# DEVICE_PRM register map
Vendor: Texas Instruments
Peripheral module from a debugger description file (folder DRA72x).
Registers are 32-bit, access per field, reset 0x0 unless marked. A register's access mark holds for its fields unless they carry their own. Offsets are as the file gives them; lines under a group give offsets from that group; [hi:lo] are bit positions; {n}, {i} and the like mark numbered series; 'fields as' and 'values as' point back to an identical list; <NAME> marks a mode.

## DEVICE_PRM
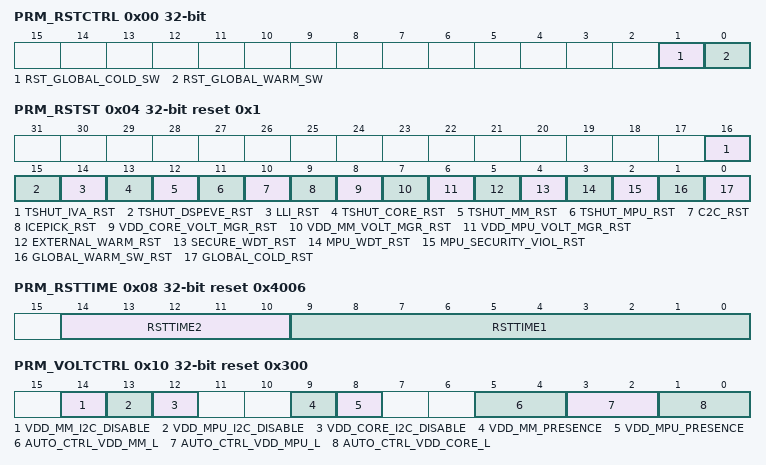
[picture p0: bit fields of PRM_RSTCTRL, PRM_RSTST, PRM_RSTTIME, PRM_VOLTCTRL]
0x00 PRM_RSTCTRL — Global software cold and warm reset control. This register is auto-cleared. Only write 1 is possible. A read returns 0 only.
  [1] RST_GLOBAL_COLD_SW rw — Global COLD software reset control. This bit is reset only upon a global cold source of reset.
    0=Global COLD software reset is cleared; 1=Triggers a global COLD software reset. The software must ensure the SDRAM is properly put in sef-refresh mode before applying this reset.
  [0] RST_GLOBAL_WARM_SW rw — Global WARM software reset control. This bit is reset upon any global source of reset (warm and cold).
    0=Global warm software reset is cleared; 1=Triggers a global warm software reset
0x04 PRM_RSTST reset 0x1 — This register logs the global reset sources. Each bit is set upon release of the domain reset signal. Must be cleared by software. [warm reset insensitive]
  [16] TSHUT_IVA_RST rw — TSHUT_IVA warm reset event. This is a source of global WARM reset.
    0=No TSHUT_MM reset; 1=TSHUT_MM reset has occurred
  [15] TSHUT_DSPEVE_RST rw — TSHUT_DSPEVE warm reset event. This is a source of global WARM reset.
    0=No TSHUT_MM reset; 1=TSHUT_MM reset has occurred
  [14] LLI_RST rw — LLI warm reset event. This is a source of global WARM reset.
    0=No LLI warm reset; 1=LLI warm reset has occurred
  [13] TSHUT_CORE_RST rw — TSHUT_CORE warm reset event. This is a source of global WARM reset.
    0=No TSHUT_CORE reset; 1=TSHUT_CORE reset has occurred
  [12] TSHUT_MM_RST rw — TSHUT_GPU warm reset event. This is a source of global WARM reset.
    0=No TSHUT_MM reset; 1=TSHUT_MM reset has occurred
  [11] TSHUT_MPU_RST rw — TSHUT_MPU warm reset event. This is a source of global WARM reset.
    0=No TSHUT_MPU reset; 1=TSHUT_MPU reset has occurred
  [10] C2C_RST rw — C2C warm reset event. This is a source of global WARM reset.
    0=No C2C warm reset; 1=C2C warm reset has occurred
  [9] ICEPICK_RST rw — IcePick reset event. This is a source of global warm reset initiated by the emulation.
    0=No ICEPICK reset; 1=IcePick reset has occurred
  [8] VDD_CORE_VOLT_MGR_RST rw — VDD_CORE voltage manager reset event This is a source of global WARM reset.
    0=No VDD_CORE voltage manager reset; 1=VDD_CORE voltage manager reset has occurred
  [7] VDD_MM_VOLT_MGR_RST rw — VDD_MM voltage manager reset event This is a source of global WARM reset.
    0=No VDD_MM voltage manager reset; 1=VDD_MM voltage manager reset has occurred
  [6] VDD_MPU_VOLT_MGR_RST rw — VDD_MPU voltage manager reset event This is a source of global WARM reset.
    0=No VDD_MPU voltage manager reset; 1=VDD_MPU voltage manager reset has occurred
  [5] EXTERNAL_WARM_RST rw — External warm reset event
    0=No global warm reset; 1=Global external warm reset has occurred
  [4] SECURE_WDT_RST rw — Secure Watchdog timer or HDCP reset event. This is a source of global WARM reset.
    0=No Secure watchdog / HDCP reset; 1=Secure wachtdog or HDCP reset has occurred
  [3] MPU_WDT_RST rw — WD_TIMER2 and MPU subsystem watchdog reset event. This is a source of global WARM reset.
    0=No reset; 1=Reset has occurred
  [2] MPU_SECURITY_VIOL_RST rw — Security violation reset event triggered by Security State Machine inside MPUSS. This is a source of global WARM reset.
    0=No security violation reset; 1=Security violation reset has occurred
  [1] GLOBAL_WARM_SW_RST rw — Global warm software reset event
    0=No global warm SW reset; 1=Global warm SW reset has occurred
  [0] GLOBAL_COLD_RST rw — Power-on (cold) reset event
    0=No power-on reset; 1=Power-on reset has occurred
0x08 PRM_RSTTIME reset 0x4006 — Reset duration control. [warm reset insensitive]
  [14:10] RSTTIME2 rw — Power domain reset duration 2 in number of RM.SYSCLK clock cycles.
  [9:0] RSTTIME1 rw — Global reset duration 1 in number of FUNC_32K_CLK clock cycles. This bit-field is only sensitive to the external power-on reset (WKUPAON_SYS_PWRON_RST reset line)
0x10 PRM_VOLTCTRL reset 0x300 — This register provides voltage domain management controls.
  [14] VDD_MM_I2C_DISABLE rw — This bit allows disabling I2C interface with powerIC for MM voltage (for debug purpose only). [warm reset insensitive]
    0=I2C_ENABLED (Normal mode: I2C is enabled.); 1=I2C_DISABLED (Debug mode: I2C is disabled.)
  [13] VDD_MPU_I2C_DISABLE rw — This bit allows disabling I2C interface with powerIC for MPU voltage (for debug purpose only). [warm reset insensitive]
    values as VDD_MM_I2C_DISABLE
  [12] VDD_CORE_I2C_DISABLE rw — This bit allows disabling I2C interface with powerIC for CORE voltage (for debug purpose only). [warm reset insensitive]
    values as VDD_MM_I2C_DISABLE
  [9] VDD_MM_PRESENCE rw — This bit control the presence of MM voltage in device. [warm reset insensitive]
    0=VOLTAGE_ABSENT (MM voltage is not present as an individual voltage: MM voltage is merged with MPU voltage if VDD_MPU_presence=1. MM voltage is merged with CORE voltage if VDD_MPU_presence=0.); 1=VOLTAGE_PRESENT (MM voltage is present on the device.)
  [8] VDD_MPU_PRESENCE rw — This bit control the presence of MPU voltage in device. [warm reset insensitive]
    0=VOLTAGE_ABSENT (MPU voltage is not present as an individual voltage: MPU voltage is merged with MM voltage if VDD_MM_presence=1. MPU voltage is merged with CORE voltage if VDD_MM_presence=0.); 1=VOLTAGE_PRESENT (MPU voltage is present on the device.)
  [5:4] AUTO_CTRL_VDD_MM_L rw — This bit field specifies the state to which the hardware can automatically transition the VDD_MM_L voltage domain.
    0=DISABLED (Voltage domain transitions are disabled.); 1=AUTO_SLEEP (Voltage domain transitions to SLEEP are enabled.); 2=AUTO_RET (Voltage domain transitions to RET are enabled.)
  [3:2] AUTO_CTRL_VDD_MPU_L rw — This bit field specifies the state to which the hardware can automatically transition the VDD_MPU_L voltage domain.
    values as AUTO_CTRL_VDD_MM_L
  [1:0] AUTO_CTRL_VDD_CORE_L rw — This bit field specifies the state to which the hardware can automatically transition the VDD_CORE_L voltage domain.
    values as AUTO_CTRL_VDD_MM_L
0x14 PRM_PWRREQCTRL — This register allows controlling the PWRREQ signal towards power IC.
  [1:0] PWRREQ_COND rw — Control upon which condition from MPU, MM and CORE voltage domains PWRREQ is de-asserted.
    0=NEVER (PWRREQ is never de-asserted); 1=SLEEP (PWRREQ is de-asserted if all voltage domain are in SLEEP, RET or OFF state. Conversely, PWRREQ is asserted upon any voltage domain entering or staying in ON state.); 2=RET (PWRREQ is de-asserted if all voltage domain are in RET or OFF state. Conversely, PWRREQ is asserted upon any voltage domain entering or staying in ON or SLEEP state.); 3=OFF (PWRREQ is de-asserted if all voltage domain are in OFF state. Conversely, PWRREQ is asserted upon any voltage domain entering or staying in ON or SLEEP or RET state.)
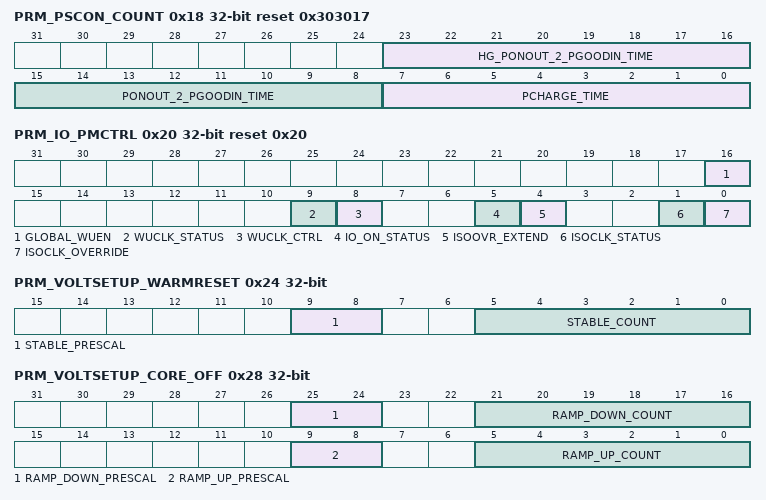
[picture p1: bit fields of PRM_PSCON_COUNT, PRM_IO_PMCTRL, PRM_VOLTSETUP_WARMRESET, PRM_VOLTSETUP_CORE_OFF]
0x18 PRM_PSCON_COUNT reset 0x303017 — This register allows controlling 2 parameters for power state controller. [warm reset insensitive]
  [23:16] HG_PONOUT_2_PGOODIN_TIME rw — The value 'NbCycles' set in this field determines the duration of the PONOUT to PGOODIN transition for power domain without DPS. The duration is computed as 8 x NbCycles of system clock cycles. Target is 10us.
  [15:8] PONOUT_2_PGOODIN_TIME rw — The value 'NbCycles' set in this field determines the duration of the PONOUT to PGOODIN transition for power domain without DPS. The duration is computed as 8 x NbCycles of system clock cycles. Target is 10us.
  [7:0] PCHARGE_TIME rw — Number of system clock cycles for the SRAM pre-charge duration. Target is 600ns.
0x1C PRM_IO_COUNT reset 0x3A — This register allows controlling DDR IO isolation removal setup. [warm reset insensitive]
  [7:0] ISO_2_ON_TIME rw — Determines the setup time of the DDR IOs going out of isolation. Counting on the system clock. Target is 1.5us.
0x20 PRM_IO_PMCTRL reset 0x20 — This register allows controlling power management features of the IOs.
  [16] GLOBAL_WUEN rw — Global IO wakeup enable. This is a gating condition to all individual IO WUEN coming from control module. Gating is done in the Spinner logic.
    0=DISABLED (All individual IO WUEN are gated in the Spinner logic (overriden to 0).); 1=ENABLED (All individual IO WUEN from control module are going to IOs.)
  [9] WUCLK_STATUS ro — Gives value of WUCLKOUT signal coming back from IO pad ring.
  [8] WUCLK_CTRL rw — Direct control on WUCLKIN signal to IO pad ring.
    0=LOW (WUCLKIN signal is driven to 0. IO wakeup daisy chain is functional as well as IO whose wakeup feature is enabled.); 1=HIGH (WUCLKIN signal is driven to 1. IO wakeup daisy chain is reset and is latching current pad states and WUEN inputs.)
  [5] IO_ON_STATUS ro — Gives the functional status of the IO ring.
    0=LOW (Part or all of the IOs are not in the ON state, that is are in isolation state.); 1=HIGH (All IOs are in the ON state.)
  [4] ISOOVR_EXTEND rw — Control non-EMIF IO isolation extension upon a device wakeup from OFF mode.
    0=NOOVERRIDE (Non-EMIF IO isolation is not extended. 'EMIF_ON' IO transition happens as soon as automatic restore is completed.); 1=OVERRIDE (Non-EMIF IO isolation is extended. 'EMIF_ON' IO transition is stalled.)
  [1] ISOCLK_STATUS ro — Gives value of ISOCLKOUT signal coming back from IO pad ring.
  [0] ISOCLK_OVERRIDE rw — Override control on ISOCLKIN signal to IO pad ring. Used at boot time when it is needed to change the mode of an IO from 1.8V default mode to 1.2V mode. When not overriden, this signal is controlled by hardware only.
    0=NOOVERRIDE (ISOCLKIN signal is not overriden.); 1=OVERRIDE (ISOCLKIN signal is overriden to active value ('1').)
0x24 PRM_VOLTSETUP_WARMRESET — This register provides bit-fields for specifying voltage stabilization duration upon a global warm reset. [warm reset insensitive]
  [9:8] STABLE_PRESCAL rw — Determines prescaler for stabilization duration counting.
    0=X32 (Ramp-up counter is incremented every 32 system clock cycles); 1=X256 (Ramp-up counter is incremented every 256 system clock cycles); 2=X2048 (Ramp-up counter is incremented every 2048 system clock cycles); 3=X16384 (Ramp-up counter is incremented every 16384 system clock cycles)
  [5:0] STABLE_COUNT rw — Determines the stabilization duration of all VDD_xxx_L regulators upon a global warm reset assertion. The duration is computed according to Stable_Prescal.
0x28 PRM_VOLTSETUP_CORE_OFF — This register provides bit-fields for specifying voltage ramp-up and ramp-down times for PRM managed external regulators. These values are used for VDD_CORE_L domain transitions with OFF state. [warm reset insensitive]
  [25:24] RAMP_DOWN_PRESCAL rw — Determines prescaler for ramp-down duration counting.
    0=X64 (Ramp-down counter is incremented every 64 system clock cycles); 1=X256 (Ramp-down counter is incremented every 256 system clock cycles); 2=X512 (Ramp-down counter is incremented every 512 system clock cycles); 3=X2048 (Ramp-down counter is incremented every 2048 system clock cycles)
  [21:16] RAMP_DOWN_COUNT rw — Determines the ramp-down duration of VDD_CORE_L regulators. The duration is computed according to Ramp_Down_Prescal.
  [9:8] RAMP_UP_PRESCAL rw — Determines prescaler for ramp-up duration counting.
    0=X64 (Ramp-up counter is incremented every 64 system clock cycles); 1=X256 (Ramp-up counter is incremented every 256 system clock cycles); 2=X512 (Ramp-up counter is incremented every 512 system clock cycles); 3=X2048 (Ramp-up counter is incremented every 2048 system clock cycles)
  [5:0] RAMP_UP_COUNT rw — Determines the ramp-up duration of VDD_CORE_L regulators. The duration is computed according to Ramp_Up_Prescal. At cold reset, PRCM assumes that VDD_CORE_L will be at a valid ON voltage before SYS_NRESPWRON is de-asserted.
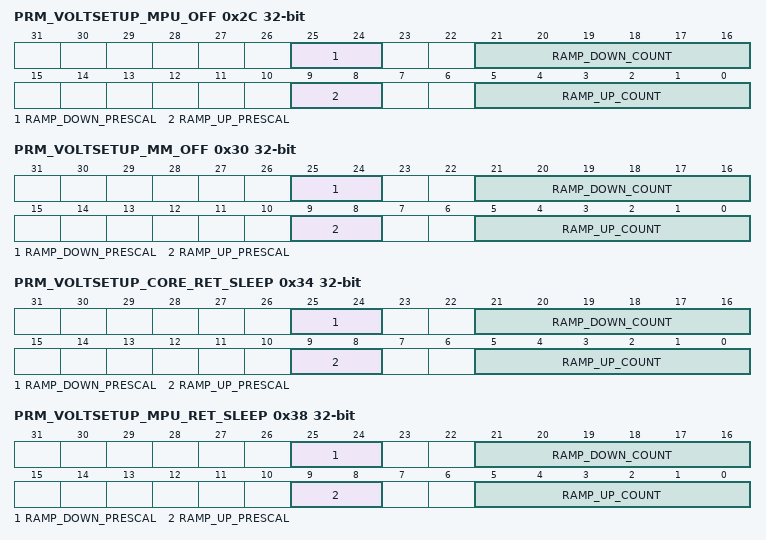
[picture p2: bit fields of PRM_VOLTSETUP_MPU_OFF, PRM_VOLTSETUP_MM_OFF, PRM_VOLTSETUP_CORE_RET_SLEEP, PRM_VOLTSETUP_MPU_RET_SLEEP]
0x2C PRM_VOLTSETUP_MPU_OFF — This register provides bit-fields for specifying voltage ramp-up and ramp-down times for PRM managed external regulators. These values are used for VDD_MPU_L domain transitions to or from OFF state. [warm reset insensitive]
  [25:24] RAMP_DOWN_PRESCAL rw — Determines prescaler for ramp-down duration counting.
    values as PRM_VOLTSETUP_CORE_OFF.RAMP_DOWN_PRESCAL
  [21:16] RAMP_DOWN_COUNT rw — Determines the ramp-down duration of VDD_MPU_L regulators. The duration is computed according to Ramp_Down_Prescal.
  [9:8] RAMP_UP_PRESCAL rw — Determines prescaler for ramp-up duration counting.
    values as PRM_VOLTSETUP_CORE_OFF.RAMP_UP_PRESCAL
  [5:0] RAMP_UP_COUNT rw — Determines the ramp-up duration of VDD_MPU_L regulators. The duration is computed according to Ramp_Up_Prescal. At cold reset, PRCM assumes that VDD_MPU_L will be at a valid ON voltage before SYS_NRESPWRON is de-asserted.
0x30 PRM_VOLTSETUP_MM_OFF — This register provides bit-fields for specifying voltage ramp-up and ramp-down times for PRM managed external regulators. These values are used for VDD_MM_L domain transitions to or from OFF state. [warm reset insensitive]
  [25:24] RAMP_DOWN_PRESCAL rw — Determines prescaler for ramp-down duration counting.
    values as PRM_VOLTSETUP_CORE_OFF.RAMP_DOWN_PRESCAL
  [21:16] RAMP_DOWN_COUNT rw — Determines the ramp-down duration of VDD_MM_L regulators. The duration is computed according to Ramp_Down_Prescal.
  [9:8] RAMP_UP_PRESCAL rw — Determines prescaler for ramp-up duration counting.
    values as PRM_VOLTSETUP_CORE_OFF.RAMP_UP_PRESCAL
  [5:0] RAMP_UP_COUNT rw — Determines the ramp-up duration of VDD_MM_L regulators. The duration is computed according to Ramp_Up_Prescal. At cold reset, PRCM assumes that VDD_MM_L will be at a valid ON voltage before SYS_NRESPWRON is de-asserted.
0x34 PRM_VOLTSETUP_CORE_RET_SLEEP — This register provides bit-fields for specifying voltage ramp-up and ramp-down times for PRM managed external regulators. These values are used for VDD_CORE_L domain transitions between ON and RET or SLEEP state. [warm reset insensitive]
  [25:24] RAMP_DOWN_PRESCAL rw — Determines prescaler for ramp-down duration counting.
    values as PRM_VOLTSETUP_CORE_OFF.RAMP_DOWN_PRESCAL
  [21:16] RAMP_DOWN_COUNT rw — Determines the ramp-down duration of VDD_CORE_L regulators. The duration is computed according to Ramp_Down_Prescal.
  [9:8] RAMP_UP_PRESCAL rw — Determines prescaler for ramp-up duration counting.
    values as PRM_VOLTSETUP_CORE_OFF.RAMP_UP_PRESCAL
  [5:0] RAMP_UP_COUNT rw — Determines the ramp-up duration of VDD_CORE_L regulators. The duration is computed according to Ramp_Up_Prescal.
0x38 PRM_VOLTSETUP_MPU_RET_SLEEP — This register provides bit-fields for specifying voltage ramp-up and ramp-down times for PRM managed external regulators. These values are used for VDD_MPU_L domain transitions between ON and RET or SLEEP state. [warm reset insensitive]
  [25:24] RAMP_DOWN_PRESCAL rw — Determines prescaler for ramp-down duration counting.
    values as PRM_VOLTSETUP_CORE_OFF.RAMP_DOWN_PRESCAL
  [21:16] RAMP_DOWN_COUNT rw — Determines the ramp-down duration of VDD_MPU_L regulators. The duration is computed according to Ramp_Down_Prescal.
  [9:8] RAMP_UP_PRESCAL rw — Determines prescaler for ramp-up duration counting.
    0=X64 (Ramp-up counter is incremented every 64 system clock cycles); 1=X256 (Ramp-up counter is incremented every 265 system clock cycles); 2=X512 (Ramp-up counter is incremented every 512 system clock cycles); 3=X2048 (Ramp-up counter is incremented every 2048 system clock cycles)
  [5:0] RAMP_UP_COUNT rw — Determines the ramp-up duration of VDD_MPU_L regulators. The duration is computed according to Ramp_Up_Prescal.
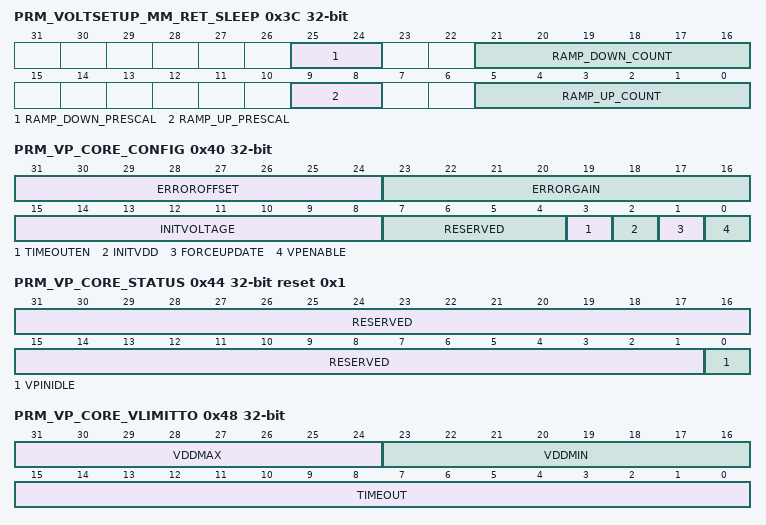
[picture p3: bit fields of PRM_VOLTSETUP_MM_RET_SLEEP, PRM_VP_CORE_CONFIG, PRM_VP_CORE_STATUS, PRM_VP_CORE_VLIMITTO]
0x3C PRM_VOLTSETUP_MM_RET_SLEEP — This register provides bit-fields for specifying voltage ramp-up and ramp-down times for PRM managed external regulators. These values are used for VDD_MM_L domain transitions between ON and RET or SLEEP state. [warm reset insensitive]
  [25:24] RAMP_DOWN_PRESCAL rw — Determines prescaler for ramp-down duration counting.
    values as PRM_VOLTSETUP_CORE_OFF.RAMP_DOWN_PRESCAL
  [21:16] RAMP_DOWN_COUNT rw — Determines the ramp-down duration of VDD_MM_L regulators. The duration is computed according to Ramp_Down_Prescal.
  [9:8] RAMP_UP_PRESCAL rw — Determines prescaler for ramp-up duration counting.
    values as PRM_VOLTSETUP_CORE_OFF.RAMP_UP_PRESCAL
  [5:0] RAMP_UP_COUNT rw — Determines the ramp-up duration of VDD_MM_L regulators. The duration is computed according to Ramp_Up_Prescal.
0x40 PRM_VP_CORE_CONFIG — This register allows the configuration of the Voltage Processor dedicated to CORE Voltage Domain (VDD_CORE_L).
  [31:24] ERROROFFSET rw — Offset value in the Error to Voltage converter (two's complement number).
  [23:16] ERRORGAIN rw — Gain value in the Error to Voltage converter (two's complement number).
  [15:8] INITVOLTAGE rw — Set the initial voltage level of the SMPS.
  [7:4] RESERVED ro — Write 0's for future compatibility. Read is undefined.
  [3] TIMEOUTEN rw — Enable or disable the timeout capability of the Voltage Controller State Machine.
    0=DIS (Timeout is disabled. Loop will wait indefinitely.); 1=EN (Timeout will occur when TIMEOUT cycles have elapsed.)
  [2] INITVDD rw — Initializes the voltage in the Voltage Processor.
    0=NEGEDGE (Reset the initialization bit.); 1=POSEDGE (The positive edge of InitVdd triggers a write of the value in the InitVoltage into the Voltage Processor.)
  [1] FORCEUPDATE rw — Forces an update of the SMPS.
    0=NEGEDGE (Reset the force bit.); 1=POSEDGE (The positive edge of ForceUpdate triggers an update of the voltage to the SMPS.)
  [0] VPENABLE rw — Enables or disables the Voltage Processor updates on SR_SInterruptz.
    0=DIS (Disables the Voltage Processor.); 1=EN (Enables the Voltage Processor.)
0x44 PRM_VP_CORE_STATUS ro reset 0x1 — This register reflects the idle state of the Voltage Processor dedicated to the CORE Voltage Domain (VDD_CORE_L. This register is read only and automatically updated.
  [31:1] RESERVED — Write 0's for future compatibility. Read is undefined.
  [0] VPINIDLE — CORE Voltage Processor idle status.
    0=NORMAL (The Voltage Processor for CORE is processing. Warm reset sensitive); 1=ISIDLE (The Voltage Processor for CORE is in idle state.)
0x48 PRM_VP_CORE_VLIMITTO rw — This register allows the configuration of the voltage limits and timeout values of the Voltage Processor dedicated to the CORE Voltage Domain (VDD_CORE_L).
  [31:24] VDDMAX — Defines the maximum voltage supply level.
  [23:16] VDDMIN — Defines the minimum voltage supply level.
  [15:0] TIMEOUT — Defines Voltage Controller maximum wait time for responses.
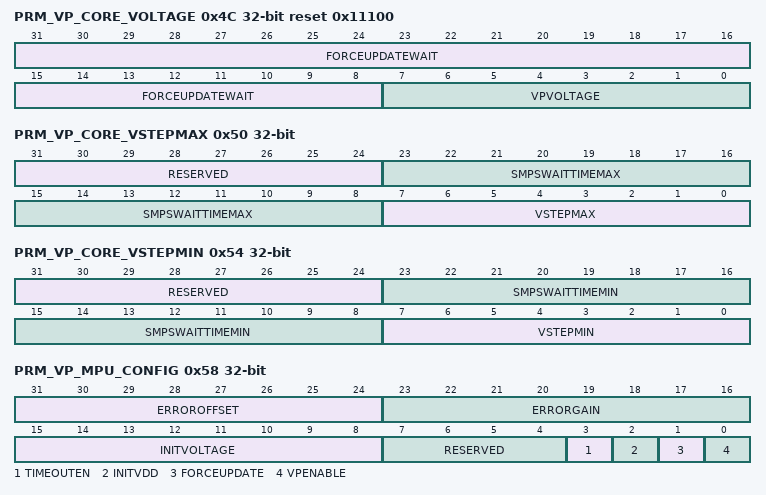
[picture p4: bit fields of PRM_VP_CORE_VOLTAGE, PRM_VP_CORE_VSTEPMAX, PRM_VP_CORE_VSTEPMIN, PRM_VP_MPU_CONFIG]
0x4C PRM_VP_CORE_VOLTAGE reset 0x11100 — This register indicates the current value of the SMPS voltage for the Voltage Processor dedicated to the CORE Voltage Domain (VDD_CORE_L).
  [31:8] FORCEUPDATEWAIT rw — The time voltage processor needs to wait for SMPS to be settled after receiving SMPS acknowledge. This wait can only be used during force_update operation.
  [7:0] VPVOLTAGE ro — Indicates the current SMPS programmed voltage.
0x50 PRM_VP_CORE_VSTEPMAX — This register allows the programming of the maximum voltage step and waiting time of the Voltage Processor dedicated to CORE Voltage Domain (VDD_CORE_L).
  [31:24] RESERVED ro — Write 0's for future compatibility. Read is undefined.
  [23:8] SMPSWAITTIMEMAX rw — Slew rate for positive voltage step (in number of cycles per step).
  [7:0] VSTEPMAX rw — Maximum voltage step
0x54 PRM_VP_CORE_VSTEPMIN — This register allows the programming of the minimum voltage step and waiting time of the Voltage Processor dedicated to the CORE Voltage Domain (VDD_CORE_L).
  [31:24] RESERVED ro — Write 0's for future compatibility. Read is undefined.
  [23:8] SMPSWAITTIMEMIN rw — Slew rate for negative voltage step (in number of cycles per step).
  [7:0] VSTEPMIN rw — Minimum voltage step
0x58 PRM_VP_MPU_CONFIG — This register allows the configuration of the Voltage Processor dedicated to MPU Voltage Domain (VDD_MPU_L).
  fields as PRM_VP_CORE_CONFIG
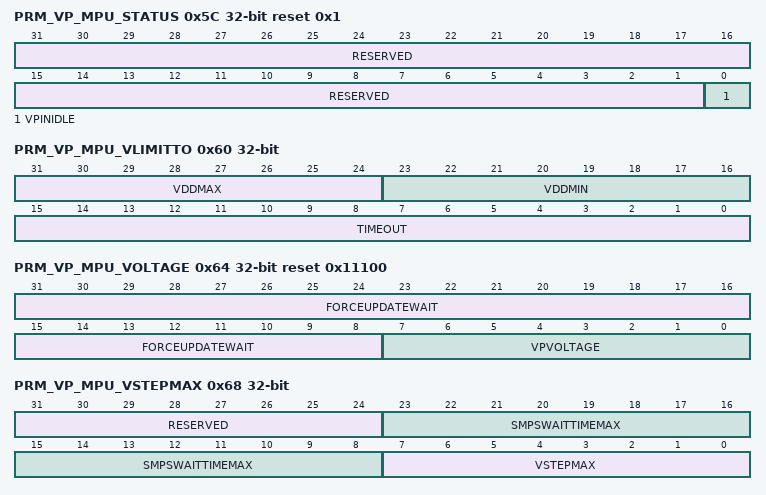
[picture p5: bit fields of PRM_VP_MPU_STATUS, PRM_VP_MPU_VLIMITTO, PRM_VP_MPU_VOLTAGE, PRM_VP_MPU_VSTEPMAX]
0x5C PRM_VP_MPU_STATUS ro reset 0x1 — This register reflects the idle state of the Voltage Processor dedicated to the MPU Voltage Domain (VDD_MPU_L. This register is read only and automatically updated.
  [31:1] RESERVED — Write 0's for future compatibility. Read is undefined.
  [0] VPINIDLE — Voltage Processor 1 idle status.
    0=NORMAL (The Voltage Processor 1 is processing.); 1=ISIDLE (The Voltage Processor 1 is in idle state.)
0x60 PRM_VP_MPU_VLIMITTO rw — This register allows the configuration of the voltage limits and timeout values of the Voltage Processor dedicated to the MPU Voltage Domain (VDD_MPU_L).
  fields as PRM_VP_CORE_VLIMITTO
0x64 PRM_VP_MPU_VOLTAGE reset 0x11100 — This register indicates the current value of the SMPS voltage for the Voltage Processor dedicated to the MPU Voltage Domain (VDD_MPU_L).
  [31:8] FORCEUPDATEWAIT rw — The time voltage processor needs to wait for SMPS to be settled after receiving SMPS acknowledge. This wait only be used during force_update operation.
  [7:0] VPVOLTAGE ro — Indicates the current SMPS programmed voltage.
0x68 PRM_VP_MPU_VSTEPMAX — This register allows the programming of the maximum voltage step and waiting time of the Voltage Processor dedicated to MPU Voltage Domain (VDD_MPU_L).
  fields as PRM_VP_CORE_VSTEPMAX
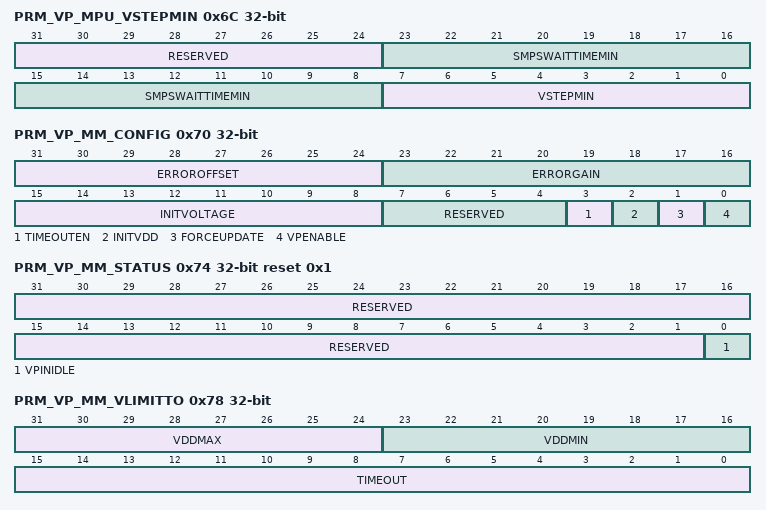
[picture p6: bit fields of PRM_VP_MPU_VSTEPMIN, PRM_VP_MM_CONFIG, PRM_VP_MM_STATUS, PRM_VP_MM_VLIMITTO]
0x6C PRM_VP_MPU_VSTEPMIN — This register allows the programming of the minimum voltage step and waiting time of the Voltage Processor dedicated to the MPU Voltage Domain (VDD_MPU_L).
  fields as PRM_VP_CORE_VSTEPMIN
0x70 PRM_VP_MM_CONFIG — This register allows the configuration of the Voltage Processor dedicated to MM Voltage Domain (VDD_MM_L).
  fields as PRM_VP_CORE_CONFIG
0x74 PRM_VP_MM_STATUS ro reset 0x1 — This register reflects the idle state of the Voltage Processor dedicated to the MPU Voltage Domain (VDD_MM_L. This register is read only and automatically updated.
  fields as PRM_VP_MPU_STATUS
0x78 PRM_VP_MM_VLIMITTO rw — This register allows the configuration of the voltage limits and timeout values of the Voltage Processor dedicated to the MM voltage Domain (VDD_MM_L).
  fields as PRM_VP_CORE_VLIMITTO
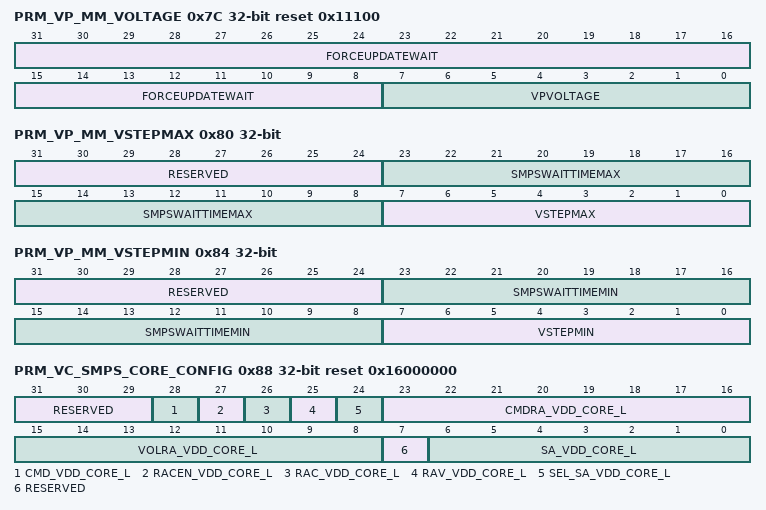
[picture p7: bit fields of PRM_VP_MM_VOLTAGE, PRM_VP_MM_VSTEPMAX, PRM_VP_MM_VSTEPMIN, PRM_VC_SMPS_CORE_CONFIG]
0x7C PRM_VP_MM_VOLTAGE reset 0x11100 — This register indicates the current value of the SMPS voltage for the Voltage Processor dedicated to the MM voltage Domain (VDD_MM_L).
  fields as PRM_VP_MPU_VOLTAGE
0x80 PRM_VP_MM_VSTEPMAX — This register allows the programming of the maximum voltage step and waiting time of the Voltage Processor dedicated to MM voltage Domain (VDD_MM_L).
  fields as PRM_VP_CORE_VSTEPMAX
0x84 PRM_VP_MM_VSTEPMIN — This register allows the programming of the minimum voltage step and waiting time of the Voltage Processor dedicated to the MM voltage Domain (VDD_MM_L).
  fields as PRM_VP_CORE_VSTEPMIN
0x88 PRM_VC_SMPS_CORE_CONFIG reset 0x16000000 — This register allows the setting of the I2C slave address of the Power IC device, the setting of the voltage configuration register address for the CORE VDD and the Command (ON/ON-Low-Power/Retention/OFF) configuration register address values for CORE VDD (if used SMPS chips have different command configuration register than voltage configuration register). [warm reset insensitive]
  [31:29] RESERVED ro — Write 0's for future compatibility. Read is undefined.
  [28] CMD_VDD_CORE_L rw — Command values (ON/ON-Low-Power/Retention/OFF voltage values) set selection for VDD_CORE_L channel
    0=MPU (VDD_CORE_L channel use VC_VAL_CMD_VDD_MPU_L set for command values); 1=CORE (VDD_CORE_L channel use VC_VAL_CMD_VDD_CORE_L set for command values)
  [27] RACEN_VDD_CORE_L rw — Enable bit for usage of RAC_VDD_CORE_L
    0=VOLRA (VDD_CORE_L channel uses VOLRA values for register address of VFSM-s commands. VFSM-s commands goes also to voltage configuration register.); 1=CMDRA (VDD_CORE_L channel uses CMDRA values for register address of VFSM-s commands. VFSM-s commands goes to different command configuration register.)
  [26] RAC_VDD_CORE_L rw — Command (ON/ON-Low-Power/Retention/OFF) configuration register address pointer for VDD_CORE_L channel
    0=SEL_MPU (Select CMDRA_VDD_MPU_L for VDD_CORE_L channel); 1=SEL_CORE (Select CMDRA_VDD_CORE_L for VDD_CORE_L channel)
  [25] RAV_VDD_CORE_L rw — Voltage configuration register address pointer for VDD_CORE_L channel.
    0=SEL_MPU (Select VOLRA_VDD_MPU_L for VDD_CORE_L channel); 1=SEL_CORE (Select VOLRA_VDD_CORE_L for VDD_CORE_L channel)
  [24] SEL_SA_VDD_CORE_L rw — Slave address pointer for VDD_CORE_L channel.
    0=SEL_MPU (Select SA_VDD_MPU_L for VDD_CORE_L channel); 1=SEL_CORE (Select SA_VDD_CORE_L for VDD_CORE_L channel)
  [23:16] CMDRA_VDD_CORE_L rw — Command (ON/ON-Low-Power /Retention/OFF) configuration register address value for VDD_CORE_L channel.(if VDD_CORE_L source has different command configuration register than voltage VDD_MPU_L)
  [15:8] VOLRA_VDD_CORE_L rw — Set the voltage configuration register address value for the VDD_CORE_L channel (if VDD_CORE_L source is placed in same chip as VDD_MPU_L source and have different voltage configuration register)
  [7] RESERVED ro — Write 0's for future compatibility. Read is undefined.
  [6:0] SA_VDD_CORE_L rw — Set the I2C slave address value for the first Power IC device.
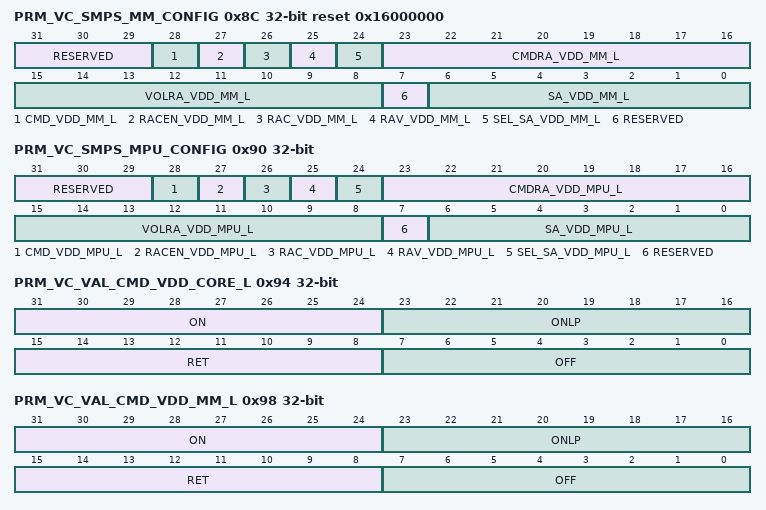
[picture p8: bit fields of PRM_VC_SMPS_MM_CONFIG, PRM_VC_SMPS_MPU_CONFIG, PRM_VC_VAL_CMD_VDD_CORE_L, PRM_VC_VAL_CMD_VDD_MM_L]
0x8C PRM_VC_SMPS_MM_CONFIG reset 0x16000000 — This register allows the setting of the I2C slave address of the Power IC device, the setting of the voltage configuration register address for the MM VDD and the Command (ON/ON-Low-Power/Retention/OFF) configuration register address values for MM VDD (if used SMPS chips have different command configuration register than voltage configuration register).. [warm reset insensitive]
  [31:29] RESERVED ro — Write 0's for future compatibility. Read is undefined.
  [28] CMD_VDD_MM_L rw — Command values (ON/ON-Low-Power/Retention/OFF voltage values) set selection for VDD_MM_L channel
    0=MPU (VDD_MM_L channel use VC_VAL_CMD_VDD_MPU_L set for command values); 1=MM (VDD_MM_L channel use VC_VAL_CMD_VDD_MM_L set for command values)
  [27] RACEN_VDD_MM_L rw — Enable bit for usage of RAC_VDD_MM_L
    0=VOLRA (VDD_MM_L channel uses VOLRA values for register address of VFSM-s commands. VFSM-s commands goes also to voltage configuration register.); 1=CMDRA (VDD_MM_L channel uses CMDRA values for register address of VFSM-s commands. VFSM-s commands goes to different command configuration register.)
  [26] RAC_VDD_MM_L rw — Command (ON/ON-Low-Power/Retention/OFF) configuration register address pointer for VDD_MM_L channel
    0=SEL_MPU (Select CMDRA_VDD_MPU_L for VDD_MM_L channel); 1=SEL_MM (Select CMDRA_VDD_MM_L for VDD_MM_L channel)
  [25] RAV_VDD_MM_L rw — Voltage configuration register address pointer for VDD_MM_L channel.
    0=SEL_MPU (Select VOLRA_VDD_MPU_L for VDD_MM_L channel); 1=SEL_MM (Select VOLRA_VDD_MM_L for VDD_MM_L channel)
  [24] SEL_SA_VDD_MM_L rw — Slave address pointer for VDD_MM_L channel.
    0=SEL_MPU (Select SA_VDD_MPU_L for VDD_MM_L channel); 1=SEL_MM (Select SA_VDD_MM_L for VDD_MM_L channel)
  [23:16] CMDRA_VDD_MM_L rw — Command (ON/ON-Low-Power /Retention/OFF) configuration register address value for VDD_MM_L channel (if VDD_MM_L source has different command configuration register than voltage VDD_MPU_L)
  [15:8] VOLRA_VDD_MM_L rw — Voltage configuration register address value for VDD_MM_L channel (if VDD_MM_L source is placed in same chip as VDD_MPU_L source and have different voltage configuration register)
  [7] RESERVED ro — Write 0's for future compatibility. Read is undefined.
  [6:0] SA_VDD_MM_L rw — Set the I2C slave address value for the second (if any) Power IC device.
0x90 PRM_VC_SMPS_MPU_CONFIG — This register allows the setting of the I2C slave address of the Power IC device, the setting of the voltage configuration register address for the MPU VDD and the Command (ON/ON-Low-Power/Retention/OFF) configuration register address values for MPU VDD (if used SMPS chips have different command configuration register than voltage configuration register). [warm reset insensitive]
  [31:29] RESERVED ro — Write 0's for future compatibility. Read is undefined.
  [28] CMD_VDD_MPU_L rw — Command values (ON/ON-Low-Power/Retention/OFF voltage values) set selection for VDD_MPU_L channel (This bit has no influence on VDD_MPU_L channel)
  [27] RACEN_VDD_MPU_L rw — Enable bit for usage of RAC_VDD_MPU_L
    0=VOLRA (VDD_MPU_L channel uses VOLRA values for register address of VFSM-s commands. VFSM-s commands goes also to voltage configuration register.); 1=CMDRA (VDD_MPU_L channel uses CMDRA values for register address of VFSM-s commands. VFSM-s commands goes to different command configuration register.)
  [26] RAC_VDD_MPU_L rw — Command (ON/ON-Low-Power/Retention/OFF) configuration register address pointer for VDD_MPU_L channel. (This bit has no influence on first VDD_MPU_L channel)
  [25] RAV_VDD_MPU_L rw — Voltage configuration register address pointer for VDD_MPU_L channel. (This bit has no influence on first VDD_MPU_L channel)
  [24] SEL_SA_VDD_MPU_L rw — Slave address pointer for VDD_MPU_L channel. (This bit has no influence on first VDD_MPU_L channel)
  [23:16] CMDRA_VDD_MPU_L rw — Command (ON/ON-Low-Power /Retention/OFF) configuration register address value for VDD_MPU_L channel.
  [15:8] VOLRA_VDD_MPU_L rw — Voltage configuration register address value for VDD_MPU_L channel.
  [7] RESERVED ro — Write 0's for future compatibility. Read is undefined.
  [6:0] SA_VDD_MPU_L rw — Set the I2C slave address value for the third (if any) Power IC device.
0x94 PRM_VC_VAL_CMD_VDD_CORE_L rw — This register allows the setting of the ON/ON-Low-Power/Retention/OFF command values for VDD_CORE_L channel. [warm reset insensitive]
  [31:24] ON — Set the ON command value.
  [23:16] ONLP — Set the ON-Low-Power command value.
  [15:8] RET — Set the RET command value.
  [7:0] OFF — Set the OFF command value.
0x98 PRM_VC_VAL_CMD_VDD_MM_L rw — This register allows the setting of the ON/ON-Low-Power/Retention/OFF command values for VDD_MM_L channel. [warm reset insensitive]
  fields as PRM_VC_VAL_CMD_VDD_CORE_L
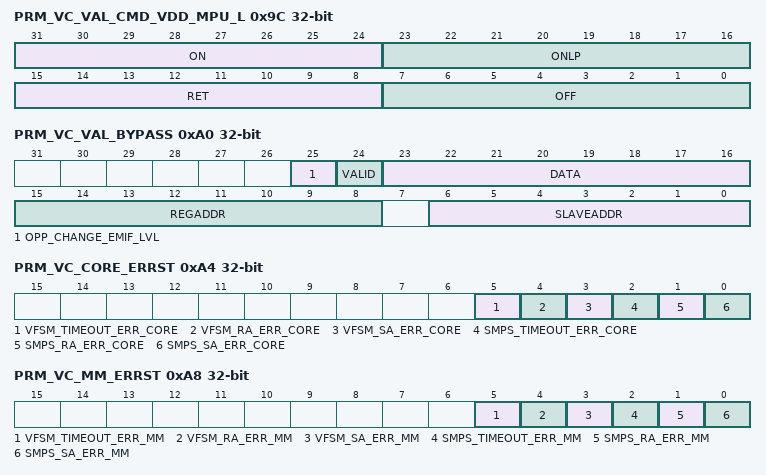
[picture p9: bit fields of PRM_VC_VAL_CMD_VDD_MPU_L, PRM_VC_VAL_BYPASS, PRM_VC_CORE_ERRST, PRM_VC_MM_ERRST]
0x9C PRM_VC_VAL_CMD_VDD_MPU_L rw — This register allows the setting of the ON/ON-Low-Power/Retention/OFF command values for VDD_MPU_L channel. [warm reset insensitive]
  fields as PRM_VC_VAL_CMD_VDD_CORE_L
0xA0 PRM_VC_VAL_BYPASS — Bypass data values register used for bypass command channel to send other configuration information (other then voltage configuration parameters) for SMPS chips which have no other configuration interface then this I2C interface and flag to indicate OPP change to EMIF to allow read/write leveling. [warm reset insensitive]
  [25] OPP_CHANGE_EMIF_LVL rw — This bit controls read-write leveling of EMIF memories (DDR3). It must be set in case OPP voltage change is done through Voltage Controller whithout passing through Voltage processor.
    0=EN_LVL (Enable leveling); 1=DIS_LVL (disable leveling)
  [24] VALID rw — This bit validates the bypass command. It is automatically cleared by HW either after getting the acknowledge back from the SMPS or if an error occurred.
    0=ACK (The last command send has been acknowledged); 1=PENDING (Pending command is being process)
  [23:16] DATA rw — Data to send to the Power IC device.
  [15:8] REGADDR rw — Set the address of Power IC device register to configure.
  [6:0] SLAVEADDR rw — Set the I2C slave address value.
0xA4 PRM_VC_CORE_ERRST — This debug register logs CORE related error status coming from Voltage Controller. Must be cleared by software.
  [all] fields
    0=OK (No error); 1=ERROR (An error has been logged)
  [5] VFSM_TIMEOUT_ERR_CORE rw — CORE voltage FSM command frame is finished but is not acknowledged by the slave, or (I2C multimaster) arbitration lost.
  [4] VFSM_RA_ERR_CORE rw — Wrong register address error for CORE voltage FSM
  [3] VFSM_SA_ERR_CORE rw — Wrong slave address error for CORE voltage FSM
  [2] SMPS_TIMEOUT_ERR_CORE rw — CORE voltage processor command frame is finished but is not acknowledged by the slave, or (I2C multimaster) arbitration lost.
  [1] SMPS_RA_ERR_CORE rw — Wrong register address error for CORE voltage processor
  [0] SMPS_SA_ERR_CORE rw — Wrong slave address error for CORE voltage processor
0xA8 PRM_VC_MM_ERRST — This debug register logs MM related error status coming from Voltage Controller. Must be cleared by software.
  [all] fields
    0=OK (No error); 1=ERROR (An error has been logged)
  [5] VFSM_TIMEOUT_ERR_MM rw — MM voltage FSM command frame is finished but is not acknowledged by the slave, or (I2C multimaster) arbitration lost.
  [4] VFSM_RA_ERR_MM rw — Wrong register address error for MM voltage FSM
  [3] VFSM_SA_ERR_MM rw — Wrong slave address error for MM voltage FSM
  [2] SMPS_TIMEOUT_ERR_MM rw — MM voltage processor command frame is finished but is not acknowledged by the slave, or (I2C multimaster) arbitration lost.
  [1] SMPS_RA_ERR_MM rw — Wrong register address error for MM voltage processor
  [0] SMPS_SA_ERR_MM rw — Wrong slave address error for MM voltage processor
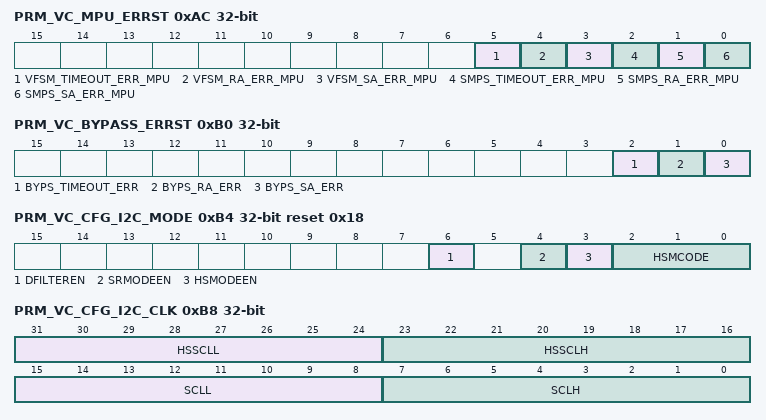
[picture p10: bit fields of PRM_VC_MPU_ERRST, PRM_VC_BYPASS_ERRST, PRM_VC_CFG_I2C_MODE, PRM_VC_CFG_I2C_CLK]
0xAC PRM_VC_MPU_ERRST — This debug register logs MPU related error status coming from Voltage Controller. Must be cleared by software.
  [all] fields
    0=OK (No error); 1=ERROR (An error has been logged)
  [5] VFSM_TIMEOUT_ERR_MPU rw — MPU voltage FSM command frame is finished but is not acknowledged by the slave, or (I2C multimaster) arbitration lost.
  [4] VFSM_RA_ERR_MPU rw — Wrong register address error for MPU voltage FSM
  [3] VFSM_SA_ERR_MPU rw — Wrong slave address error for MPU voltage FSM
  [2] SMPS_TIMEOUT_ERR_MPU rw — MPU voltage processor command frame is finished but is not acknowledged by the slave, or (I2C multimaster) arbitration lost.
  [1] SMPS_RA_ERR_MPU rw — Wrong register address error for MPU voltage processor
  [0] SMPS_SA_ERR_MPU rw — Wrong slave address error for MPU voltage processor
0xB0 PRM_VC_BYPASS_ERRST — This debug register logs BYPASS related error status coming from Voltage Controller. Must be cleared by software.
  [all] fields
    0=OK (No error); 1=ERROR (An error has been logged)
  [2] BYPS_TIMEOUT_ERR rw — BYPASS command frame is finished but is not acknowledged by the slave, or (I2C multimaster) arbitration lost.
  [1] BYPS_RA_ERR rw — Wrong register address error for BYPASS command
  [0] BYPS_SA_ERR rw — Wrong slave address error for BYPASS command
0xB4 PRM_VC_CFG_I2C_MODE reset 0x18 — I2C configuration register. [warm reset insensitive]
  [6] DFILTEREN rw — This field enables double filter procedure for I2C input lines
    0=DFILTER_EN1 (I2C bus digital filter rejects all glitches smaller than 1 sytem clock cycle); 1=DFILTER_EN2 (I2C bus digital filter rejects all glitches smaller than 2 sytem clock cycle)
  [4] SRMODEEN rw — Enables the I2C repeated start operation mode (effect of holding the SCL and SDA lines low, in effect blocking the I2C bus from losing arbitration between repeated start points). Use of this feature results from a trade-off between speed and power consumption of I2C interface.
    0=DIS_SR (Disables the repeated start operation mode); 1=EN_SR (Enables the repeated start operation mode)
  [3] HSMODEEN rw — Enables I2C bus High Speed mode.
    0=DIS_HS (Disables the I2C high speed mode); 1=EN_HS (Enables the I2C high speed mode)
  [2:0] HSMCODE rw — Master code value for I2C High Speed preamble transmission.
0xB8 PRM_VC_CFG_I2C_CLK rw — I2C Interface clock configuration parameters. [warm reset insensitive]
  [31:24] HSSCLL — Number of the system clock cycles, necessary to count the low period of the I2C clock signal, when the I2C interface runs in High-Speed mode of operation.
  [23:16] HSSCLH — Number of the system clock cycles, necessary to count the high period of the I2C clock signal, when the I2C interface runs in High-Speed mode of operation.
  [15:8] SCLL — Number of the system clock cycles, necessary to count the low period of the I2C clock signal, when the I2C interface runs in Fast mode of operation.
  [7:0] SCLH — Number of the system clock cycles, necessary to count the high period of the I2C clock signal, when the I2C interface runs in Fast mode of operation.
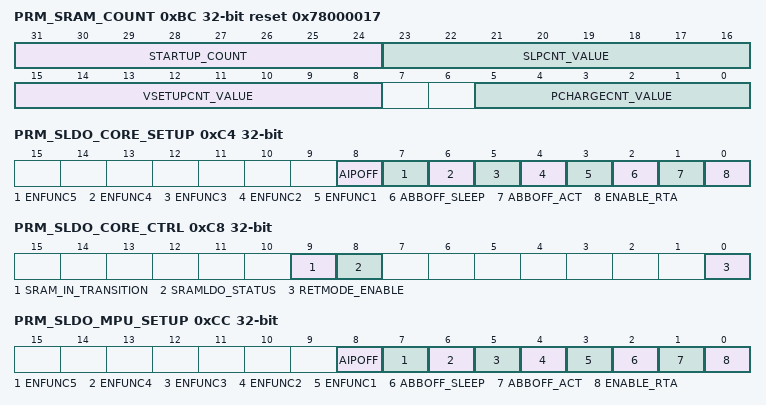
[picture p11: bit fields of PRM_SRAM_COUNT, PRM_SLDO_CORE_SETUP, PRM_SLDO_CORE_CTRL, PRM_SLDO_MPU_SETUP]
0xBC PRM_SRAM_COUNT reset 0x78000017 — Common setup for SRAM LDO transition counters. Applies to all voltage domains. [warm reset insensitive]
  [31:24] STARTUP_COUNT rw — Determines the start-up duration of SRAM and ABB LDO. The duration is computed as 16 x NbCycles of system clock cycles. Target is 50us.
  [23:16] SLPCNT_VALUE rw — Delay between retention/off assertion of last SRAM bank and SRAMALLRET signal to LDO is driven high. Counting on system clock. Target is 2us.
  [15:8] VSETUPCNT_VALUE rw — SRAM LDO rampup time from retention to active mode. The duration is computed as 8 x NbCycles of system clock cycles. Target is 30us.
  [5:0] PCHARGECNT_VALUE rw — Delay between de-assertion of standby_rta_ret_on and standby_rta_ret_good. Counting on system clock. Target is 600ns.
0xC0 PRM_SRAM_WKUP_SETUP — Setup of memory in WKUP voltage domain. [warm reset insensitive]
  [0] ENABLE_RTA rw — Control for HD memory RTA feature. After PowerOn reset and Efuse sensing, this bitfield is automatically loaded with an Efuse value from control module. Bitfield remains writable after this.
    0=RTA_DISABLED (HD memory RTA feature is disabled); 1=RTA_ENABLED (HD memory RTA feature is enabled)
0xC4 PRM_SLDO_CORE_SETUP — Setup of the SRAM LDO for CORE voltage domain. [warm reset insensitive]
  [8] AIPOFF rw — Override on AIPOFF input of SRAM LDO.
    0=NO_OVERRIDE (AIPOFF signal is not overriden); 1=OVERRIDE (AIPOFF signal is overriden to '1'. Corresponding SRAM LDO is disabled and in HZ mode.)
  [7] ENFUNC5 rw — ENFUNC5 input of SRAM LDO.
    0=ONE_STEP (Active to retention is a one step transfer); 1=TWO_STEP (Active to retention is a two steps transfer)
  [6] ENFUNC4 rw — ENFUNC4 input of SRAM LDO.
    0=EXT_CLOCK (One external clock is supplied); 1=NO_EXT_CLOCK (No external clock is supplied)
  [5] ENFUNC3 rw — ENFUNC3 input of SRAM LDO. After PowerOn reset and Efuse sensing, this bitfield is automatically loaded with an Efuse value from control module. Bitfield remains writable after this.
    0=SUB_REGUL_DISABLED (Sub regulation is disabled); 1=SUB_REGUL_ENABLED (Sub regulation is enabled)
  [4] ENFUNC2 rw — ENFUNC2 input of SRAM LDO. After PowerOn reset and Efuse sensing, this bitfield is automatically loaded with an Efuse value from control module. Bitfield remains writable after this.
    0=EXT_CAP (External cap is used); 1=NO_EXT_CAP (External cap is not used)
  [3] ENFUNC1 rw — ENFUNC1 input of SRAM LDO. After PowerOn reset and Efuse sensing, this bitfield is automatically loaded with an Efuse value from control module. Bitfield remains writable after this.
    0=SHORT_PROT_DISABLED (Short circuit protection is disabled); 1=SHORT_PROT_ENABLED (Short circuit protection is enabled)
  [2] ABBOFF_SLEEP rw — Determines whether SRAMNWA is supplied by VDDS or VDDAR during deep-sleep. After PowerOn reset and Efuse sensing, this bitfield is automatically loaded with an Efuse value from control module. Bitfield remains writable after this.
    0=SRAMNW_SLP_VDDS (SRAMNWA supplied with VDDS); 1=SRAMNW_SLP_VDDAR (SRAMNWA supplied with VDDAR)
  [1] ABBOFF_ACT rw — Determines whether SRAMNWA is supplied by VDDS or VDDAR during active mode. After PowerOn reset and Efuse sensing, this bitfield is automatically loaded with an Efuse value from control module. Bitfield remains writable after this.
    0=SRAMNW_ACT_VDDS (SRAMNWA supplied with VDDS); 1=SRAMNW_ACT_VDDAR (SRAMNWA supplied with VDDAR)
  [0] ENABLE_RTA rw — Control for HD memory RTA feature. After PowerOn reset and Efuse sensing, this bitfield is automatically loaded with an Efuse value from control module. Bitfield remains writable after this.
    values as PRM_SRAM_WKUP_SETUP.ENABLE_RTA
0xC8 PRM_SLDO_CORE_CTRL ro — Control and status of the SRAM LDO for CORE voltage domain. [warm reset insensitive]
  [9] SRAM_IN_TRANSITION — Status indicating SRAM LDO state machine state.
    0=IDLE (SRAM LDO state machine is stable); 1=IN_TRANSITION (SRAM LDO state machine is in transition state)
  [8] SRAMLDO_STATUS
    0=ACTIVE (SRAMLDO is in ACTIVE mode.); 1=RETENTION (SRAMLDO is on RETENTION mode.)
  [0] RETMODE_ENABLE — Control if the SRAM LDO retention mode is used or not.
    0=DISABLED (SRAM LDO is not allowed to go to RET mode)
0xCC PRM_SLDO_MPU_SETUP — Setup of the SRAM LDO for MPU voltage domain. [warm reset insensitive]
  fields as PRM_SLDO_CORE_SETUP
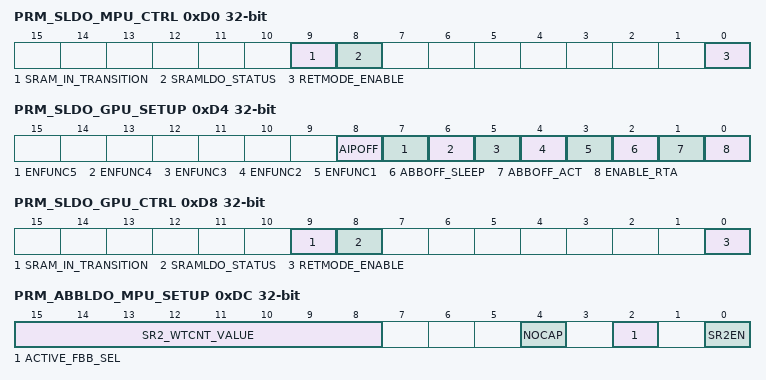
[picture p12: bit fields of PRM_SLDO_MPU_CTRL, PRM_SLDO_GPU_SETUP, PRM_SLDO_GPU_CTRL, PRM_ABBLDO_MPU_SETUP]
0xD0 PRM_SLDO_MPU_CTRL — Control and status of the SRAM LDO for MPU voltage domain. [warm reset insensitive]
  [9] SRAM_IN_TRANSITION ro — Status indicating SRAM LDO state machine state.
    values as PRM_SLDO_CORE_CTRL.SRAM_IN_TRANSITION
  [8] SRAMLDO_STATUS ro
    values as PRM_SLDO_CORE_CTRL.SRAMLDO_STATUS
  [0] RETMODE_ENABLE rw — Control if the SRAM LDO retention mode is used or not.
    0=DISABLED (SRAM LDO is not allowed to go to RET mode); 1=ENABLED (SRAM LDO go to RET mode when all memory of voltage domain are OFF or RET)
0xD4 PRM_SLDO_GPU_SETUP — Setup of the SRAM LDO for GPU voltage domain. [warm reset insensitive]
  fields as PRM_SLDO_CORE_SETUP
0xD8 PRM_SLDO_GPU_CTRL — Control and status of the SRAM LDO for GPU voltage domain. [warm reset insensitive]
  fields as PRM_SLDO_MPU_CTRL
0xDC PRM_ABBLDO_MPU_SETUP — Selects the MPU_ABB LDO mode.
  [15:8] SR2_WTCNT_VALUE rw — LDO settling time for active-mode OPP change. Counting at a 16 system clock cycles rate. Target is 50us. [warm reset insensitive]
  [4] NOCAP rw — Defines whether ABB LDO is cap-less or not. After PowerOn reset and Efuse sensing, this bitfield is automatically loaded with an Efuse value from control module. Bitfield remains writable after this. [warm reset insensitive]
    0=CAP (ABB LDO uses an external cap); 1=NOCAP (ABB LDO does not use an external cap)
  [2] ACTIVE_FBB_SEL rw — Defines ABB LDO mode when voltage is in slow fast OPP. [warm reset insensitive]
    0=BYPASS (ABB LDO is in bypass mode); 1=FBB (ABB LDO is in FBB mode)
  [0] SR2EN rw — Enable ABB power management
    0=BYPASS (ABB LDO is put in bypass mode); 1=FUNCTIONAL (ABB LDO will operate accordingly to settings)
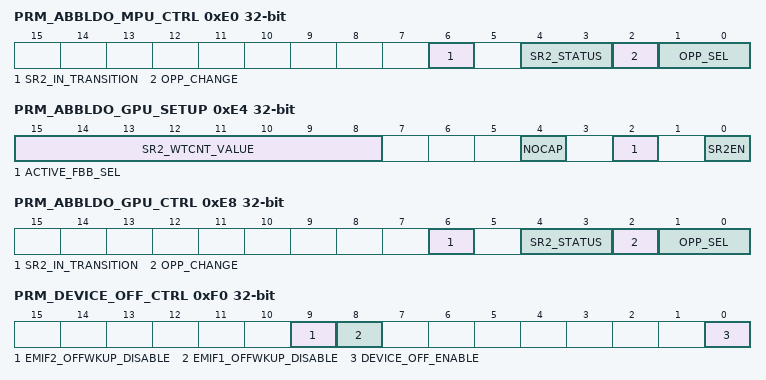
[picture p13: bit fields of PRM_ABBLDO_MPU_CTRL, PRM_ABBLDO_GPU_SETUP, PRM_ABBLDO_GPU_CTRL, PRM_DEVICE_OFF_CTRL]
0xE0 PRM_ABBLDO_MPU_CTRL — Control and Status of ABB on MPU voltage domain. [warm reset insensitive]
  [6] SR2_IN_TRANSITION ro — Indicates VBBLDO_CON is or is not in transition state. This output should be used by programming interface to clear OPP_CHANGE bit as an indication of OPP change completion.
    0=IDLE; 1=INTRANSITION (Indicates that VBBLDO_CON is in transition and SR2_STATUS bits are not stable to read.)
  [4:3] SR2_STATUS ro — Indicate ABB LDO current operation status
    0=BYPASS (ABB LDO is placed in bypass mode.); 2=FBB (ABB LDO is placed in FBB active mode.)
  [2] OPP_CHANGE rw — When OPP_CHANGE is set to 1, VBBLDO_CON samples OPP_SEL ACTIVE_FBB_SEL upon detecting rising edge. VBBLDO_CON asserts signal SR2_IN_TRANSITION in response to OPP_CHANGE. OPP_CHANGE should be cleared to 0 when SR2_IN_TRANSITION from VBBLDO_CON is de-asserted.
  [1:0] OPP_SEL rw — To control the ABB LDO (FBB/RBB) at a given OPP, set to 0x1. Refer to.
    0=DEFAULT_NOMINAL; 1=FASTOPP
0xE4 PRM_ABBLDO_GPU_SETUP — Selects the GPU_ABB LDO mode.
  fields as PRM_ABBLDO_MPU_SETUP
0xE8 PRM_ABBLDO_GPU_CTRL — Control and Status of ABB on GPU voltage domain. [warm reset insensitive]
  fields as PRM_ABBLDO_MPU_CTRL
0xEC PRM_BANDGAP_SETUP reset 0x78 — Setup of the bandgap. [warm reset insensitive]
  [7:0] STARTUP_COUNT rw — Determines the start-up duration of BANDGAP. The duration is computed as 32 x NbCycles of system clock cycles. Target is 100us.
0xF0 PRM_DEVICE_OFF_CTRL — This register is used to control device OFF transition.
  [9] EMIF2_OFFWKUP_DISABLE rw — Controls the EMIF2_DEVICE_OFFWKUP_CORESRTACTST notifier sent to EMIF1 upon a device wakeup from OFF mode. [warm reset insensitive]
    0=ENABLED (Notifier is activated.); 1=DISABLED (Notifier is not activated - stays low)
  [8] EMIF1_OFFWKUP_DISABLE rw — Controls the EMIF1_DEVICE_OFFWKUP_CORESRTACTST notifier sent to EMIF2 upon a device wakeup from OFF mode. [warm reset insensitive]
    values as EMIF2_OFFWKUP_DISABLE
  [0] DEVICE_OFF_ENABLE rw — Controls transition to device OFF mode.
    0=DISABLED (Device is not allowed to perform transition to OFF mode); 1=ENABLED (Device is allowed to perform transition to OFF mode as soon as all power domains in MPU, MM and CORE voltage are in OFF or OSWRET state (open switch retention))
0xF4 PRM_PHASE1_CNDP ro reset 0x4A05E000 — This register stores the start descriptor address of automatic restore phase1. [warm reset insensitive]
  [31:0] PHASE1_CNDP — Start descriptor address of automatic restore phase1. Hard-coded to SAR_ROM base address.
0xF8 PRM_PHASE2A_CNDP ro reset 0x4A05E030 — This register stores the start descriptor address of automatic restore phase2A. [warm reset insensitive]
  [31:0] PHASE2A_CNDP — Start descriptor address of automatic restore phase2A. Hard-coded to SAR_ROM base address + 0x30.
0xFC PRM_PHASE2B_CNDP ro reset 0x4A05E060 — This register stores the start descriptor address of automatic restore phase2B. [warm reset insensitive]
  [31:0] PHASE2B_CNDP — Start descriptor address of automatic restore phase2B. Hard-coded to SAR_ROM base address + 0x60.
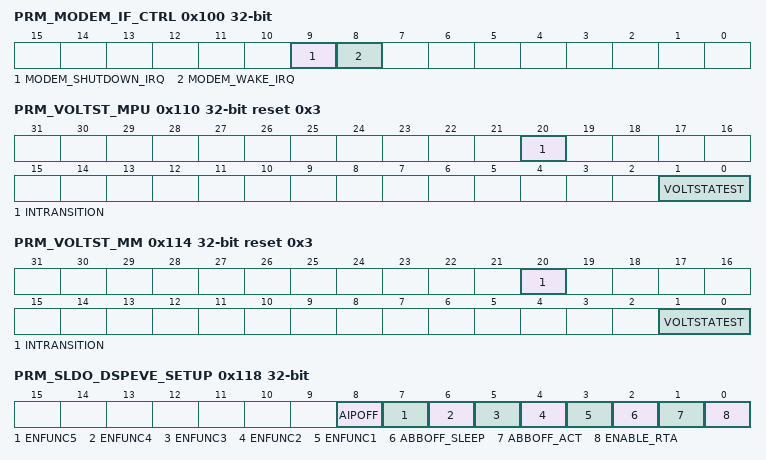
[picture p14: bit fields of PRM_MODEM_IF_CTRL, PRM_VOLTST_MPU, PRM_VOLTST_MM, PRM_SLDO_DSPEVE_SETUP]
0x100 PRM_MODEM_IF_CTRL — This register is used to control dedicated interfaces between on-chip modem and APE.
  [9] MODEM_SHUTDOWN_IRQ rw — Controls an interrupt signal to shutdown modem.
    0=INACTIVE (Interrupt is inactive); 1=ACTIVE (Interrupt is active)
  [8] MODEM_WAKE_IRQ rw — Controls an interrupt signal to wakeup modem.
    values as MODEM_SHUTDOWN_IRQ
0x110 PRM_VOLTST_MPU ro reset 0x3 — This register provides a status on the current MPU voltage domain state. [warm reset insensitive]
  [20] INTRANSITION — Domain transition status
    0=NO (No on-going transition on voltage domain); 1=ONGOING (Voltage domain transition is in progress.)
  [1:0] VOLTSTATEST — Current voltage state status
    0=OFF (Voltage domain is OFF); 1=RET (Voltage domain is in RETENTION); 2=SLEEP (Voltage domain is SLEEP); 3=ON (Voltage domain is ON)
0x114 PRM_VOLTST_MM ro reset 0x3 — This register provides a status on the current MM voltage domain state. [warm reset insensitive]
  fields as PRM_VOLTST_MPU
0x118 PRM_SLDO_DSPEVE_SETUP — Setup of the SRAM LDO for DSPEVE voltage domain. [warm reset insensitive]
  fields as PRM_SLDO_CORE_SETUP
0x11C PRM_SLDO_IVA_SETUP — Setup of the SRAM LDO for IVA voltage domain. [warm reset insensitive]
  fields as PRM_SLDO_CORE_SETUP
0x120 PRM_ABBLDO_DSPEVE_CTRL — Control and Status of ABB on DSPEVE voltage domain. [warm reset insensitive]
  [6] SR2_IN_TRANSITION ro — Indicates VBBLDO_CON is or is not in transition state. This output should be used by programming interface to clear OPP_CHANGE bit as an indication of OPP change completion.
    0=IDLE; 1=INTRANSITION (Indicates that VBBLDO_CON is in transition and SR2_STATUS bits are not stable to read.Updated PRM_ABBLDO_DSPEVE_CTRL register description.)
  [4:3] SR2_STATUS ro — Indicate ABB LDO current operation status
    values as PRM_ABBLDO_MPU_CTRL.SR2_STATUS
  [2] OPP_CHANGE rw — When OPP_CHANGE is set to 1, VBBLDO_CON samples OPP_SEL ACTIVE_FBB_SEL upon detecting rising edge. VBBLDO_CON asserts signal SR2_IN_TRANSITION in response to OPP_CHANGE. OPP_CHANGE should be cleared to 0 when SR2_IN_TRANSITION from VBBLDO_CON is de-asserted.
  [1:0] OPP_SEL rw — To control the ABB LDO (FBB/RBB) at a given OPP, set to 0x1. Refer to.
    0=DEFAULT_NOMINAL; 1=FASTOPP
0x124 PRM_ABBLDO_IVA_CTRL — Control and Status of ABB on IVA voltage domain. [warm reset insensitive]
  [6] SR2_IN_TRANSITION ro — Indicates VBBLDO_CON is or is not in transition state. This output should be used by programming interface to clear OPP_CHANGE bit as an indication of OPP change completion.
    0=IDLE; 1=INTRANSITION (Indicates that VBBLDO_CON is in transition and SR2_STATUS bits are not stable to read.Updated PRM_ABBLDO_IVA_CTRL register description.)
  [4:3] SR2_STATUS ro — Indicate ABB LDO current operation status
    values as PRM_ABBLDO_MPU_CTRL.SR2_STATUS
  [2] OPP_CHANGE rw — When OPP_CHANGE is set to 1, VBBLDO_CON samples OPP_SEL ACTIVE_FBB_SEL upon detecting rising edge. VBBLDO_CON asserts signal SR2_IN_TRANSITION in response to OPP_CHANGE. OPP_CHANGE should be cleared to 0 when SR2_IN_TRANSITION from VBBLDO_CON is de-asserted.
  [1:0] OPP_SEL rw — To control the ABB LDO (FBB/RBB) at a given OPP, set to 0x1. Refer to.
    0=DEFAULT_NOMINAL; 1=FASTOPP
0x128 PRM_SLDO_DSPEVE_CTRL — Control and status of the SRAM LDO for CORE voltage domain. [warm reset insensitive]
  fields as PRM_SLDO_MPU_CTRL
0x12C PRM_SLDO_IVA_CTRL — Control and status of the SRAM LDO for CORE voltage domain. [warm reset insensitive]
  fields as PRM_SLDO_MPU_CTRL
0x130 PRM_ABBLDO_DSPEVE_SETUP — Selects the GPU_ABB LDO mode.
  fields as PRM_ABBLDO_MPU_SETUP
0x134 PRM_ABBLDO_IVA_SETUP — Selects the GPU_ABB LDO mode.
  fields as PRM_ABBLDO_MPU_SETUP
